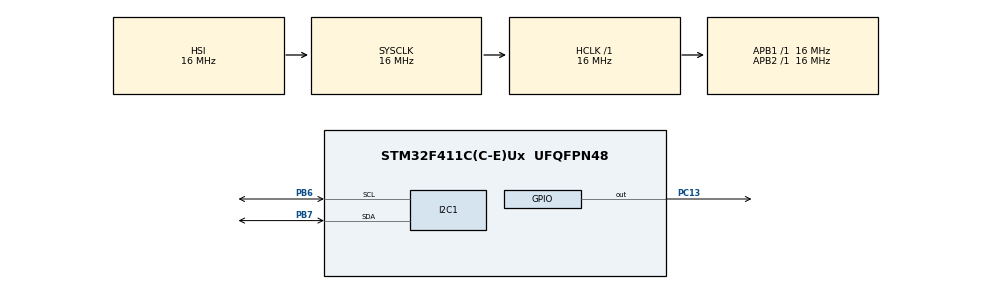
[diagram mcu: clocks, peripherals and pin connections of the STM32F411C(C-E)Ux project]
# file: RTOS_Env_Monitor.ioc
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FREERTOS.Tasks01=defaultTask,24,128,StartDefaultTask,Default,NULL,Dynamic,NULL,NULL
FREERTOS.configCHECK_FOR_STACK_OVERFLOW=1
FREERTOS.configUSE_MALLOC_FAILED_HOOK=1
Mcu.Family=STM32F4
Mcu.Name=STM32F411C(C-E)Ux
Mcu.Package=UFQFPN48
NVIC.PriorityGroup=NVIC_PRIORITYGROUP_4
NVIC.TIM1_UP_TIM10_IRQn=true\:15\:0\:false\:false\:true\:false\:false\:true\:true
NVIC.TimeBase=TIM1_UP_TIM10_IRQn
NVIC.TimeBaseIP=TIM1
PB6.Mode=I2C
PB6.Signal=I2C1_SCL
PB7.Mode=I2C
PB7.Signal=I2C1_SDA
PC13-ANTI_TAMP.Signal=GPIO_Output
ProjectManager.HeapSize=0x200
ProjectManager.StackSize=0x400
ProjectManager.TargetToolchain=STM32CubeIDE
RCC.AHBFreq_Value=16000000
RCC.APB1Freq_Value=16000000
RCC.APB2Freq_Value=16000000
RCC.CortexFreq_Value=16000000
RCC.HSE_VALUE=25000000
RCC.HSI_VALUE=16000000
RCC.LSE_VALUE=32768
RCC.SYSCLKFreq_VALUE=16000000
RCC.VCOOutputFreq_Value=192000000
VP_FREERTOS_VS_CMSIS_V2.Mode=CMSIS_V2
VP_SYS_VS_tim1.Mode=TIM1
board=custom

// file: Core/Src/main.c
/* USER CODE BEGIN Header */
/**
  ******************************************************************************
  * @file           : main.c
  * @brief          : Main program body
  ******************************************************************************
  * @attention
  *
  * Copyright (c) 2026 STMicroelectronics.
  * All rights reserved.
  *
  * This software is licensed under terms that can be found in the LICENSE file
  * in the root directory of this software component.
  * If no LICENSE file comes with this software, it is provided AS-IS.
  *
  ******************************************************************************
  */
/* USER CODE END Header */
#include "main.h"
#include "cmsis_os.h"

/* USER CODE BEGIN PD */
typedef struct {
	float temperature;
	float humidity;
	uint32_t timestamp;
} SensorData_t;
/* USER CODE END PD */

I2C_HandleTypeDef hi2c1;

/* Definitions for defaultTask */
osThreadId_t defaultTaskHandle;
const osThreadAttr_t defaultTask_attributes = {
  .name = "defaultTask",
  .stack_size = 128 * 4,
  .priority = (osPriority_t) osPriorityNormal,
};
/* USER CODE BEGIN PV */
osMessageQueueId_t sensorQueueHandle;
osMutexId_t i2cMutexHandle;
/* USER CODE END PV */

void SystemClock_Config(void);
static void MX_GPIO_Init(void);
static void MX_I2C1_Init(void);
void StartDefaultTask(void *argument);

/* USER CODE BEGIN PFP */
void Sensor_Task(void *argument);
void Comms_Task(void *argument);
void Processing_Task(void *argument);
void Display_Task(void *argument);
/* USER CODE END PFP */

int main(void)
{

  /* MCU Configuration--------------------------------------------------------*/

  /* Reset of all peripherals, Initializes the Flash interface and the Systick. */
  HAL_Init();

  /* Configure the system clock */
  SystemClock_Config();

  /* Initialize all configured peripherals */
  MX_GPIO_Init();
  MX_I2C1_Init();

  /* Init scheduler */
  osKernelInitialize();

  /* USER CODE BEGIN RTOS_MUTEX */
  /* add mutexes, ... */

  i2cMutexHandle = osMutexNew(NULL);
  /* USER CODE END RTOS_MUTEX */

  /* USER CODE BEGIN RTOS_QUEUES */
  /* add queues, ... */
  sensorQueueHandle = osMessageQueueNew(5, sizeof(SensorData_t), NULL);
  /* USER CODE END RTOS_QUEUES */

  /* Create the thread(s) */
  /* creation of defaultTask */
  defaultTaskHandle = osThreadNew(StartDefaultTask, NULL, &defaultTask_attributes);

  /* USER CODE BEGIN RTOS_THREADS */
  osThreadAttr_t sensor_attr = { .name = "SensorTask", .priority = osPriorityHigh, .stack_size = 128 * 4 };
  osThreadAttr_t comms_attr = { .name = "CommsTask", .priority = osPriorityAboveNormal, .stack_size = 128 * 4 };
  osThreadAttr_t process_attr = { .name = "ProcessTask", .priority = osPriorityNormal, .stack_size = 128 * 4 };
  osThreadAttr_t display_attr = { .name = "DisplayTask", .priority = osPriorityLow, .stack_size = 128 * 4 };

  osThreadNew(Sensor_Task, NULL, &sensor_attr);
  osThreadNew(Comms_Task, NULL, &comms_attr);
  osThreadNew(Processing_Task, NULL, &process_attr);
  osThreadNew(Display_Task, NULL, &display_attr);
  /* add threads, ... */
  /* USER CODE END RTOS_THREADS */

  /* Start scheduler */
  osKernelStart();

  /* We should never get here as control is now taken by the scheduler */

  /* Infinite loop */
  while (1)
  {

  }
}

void SystemClock_Config(void)
{
  RCC_OscInitTypeDef RCC_OscInitStruct = {0};
  RCC_ClkInitTypeDef RCC_ClkInitStruct = {0};

  /** Configure the main internal regulator output voltage
  */
  __HAL_RCC_PWR_CLK_ENABLE();
  __HAL_PWR_VOLTAGESCALING_CONFIG(PWR_REGULATOR_VOLTAGE_SCALE1);

  /** Initializes the RCC Oscillators according to the specified parameters
  * in the RCC_OscInitTypeDef structure.
  */
  RCC_OscInitStruct.OscillatorType = RCC_OSCILLATORTYPE_HSI;
  RCC_OscInitStruct.HSIState = RCC_HSI_ON;
  RCC_OscInitStruct.HSICalibrationValue = RCC_HSICALIBRATION_DEFAULT;
  RCC_OscInitStruct.PLL.PLLState = RCC_PLL_NONE;
  if (HAL_RCC_OscConfig(&RCC_OscInitStruct) != HAL_OK)
  {
    Error_Handler();
  }

  /** Initializes the CPU, AHB and APB buses clocks
  */
  RCC_ClkInitStruct.ClockType = RCC_CLOCKTYPE_HCLK|RCC_CLOCKTYPE_SYSCLK
                              |RCC_CLOCKTYPE_PCLK1|RCC_CLOCKTYPE_PCLK2;
  RCC_ClkInitStruct.SYSCLKSource = RCC_SYSCLKSOURCE_HSI;
  RCC_ClkInitStruct.AHBCLKDivider = RCC_SYSCLK_DIV1;
  RCC_ClkInitStruct.APB1CLKDivider = RCC_HCLK_DIV1;
  RCC_ClkInitStruct.APB2CLKDivider = RCC_HCLK_DIV1;

  if (HAL_RCC_ClockConfig(&RCC_ClkInitStruct, FLASH_LATENCY_0) != HAL_OK)
  {
    Error_Handler();
  }
}

static void MX_I2C1_Init(void)
{

  hi2c1.Instance = I2C1;
  hi2c1.Init.ClockSpeed = 100000;
  hi2c1.Init.DutyCycle = I2C_DUTYCYCLE_2;
  hi2c1.Init.OwnAddress1 = 0;
  hi2c1.Init.AddressingMode = I2C_ADDRESSINGMODE_7BIT;
  hi2c1.Init.DualAddressMode = I2C_DUALADDRESS_DISABLE;
  hi2c1.Init.OwnAddress2 = 0;
  hi2c1.Init.GeneralCallMode = I2C_GENERALCALL_DISABLE;
  hi2c1.Init.NoStretchMode = I2C_NOSTRETCH_DISABLE;
  if (HAL_I2C_Init(&hi2c1) != HAL_OK)
  {
    Error_Handler();
  }

}

static void MX_GPIO_Init(void)
{
  GPIO_InitTypeDef GPIO_InitStruct = {0};

  /* GPIO Ports Clock Enable */
  __HAL_RCC_GPIOC_CLK_ENABLE();
  __HAL_RCC_GPIOB_CLK_ENABLE();

  /*Configure GPIO pin Output Level */
  HAL_GPIO_WritePin(GPIOC, GPIO_PIN_13, GPIO_PIN_RESET);

  /*Configure GPIO pin : PC13 */
  GPIO_InitStruct.Pin = GPIO_PIN_13;
  GPIO_InitStruct.Mode = GPIO_MODE_OUTPUT_PP;
  GPIO_InitStruct.Pull = GPIO_NOPULL;
  GPIO_InitStruct.Speed = GPIO_SPEED_FREQ_LOW;
  HAL_GPIO_Init(GPIOC, &GPIO_InitStruct);

}

/* USER CODE BEGIN 4 */

extern I2C_HandleTypeDef hi2c1;

#include <math.h>
#include <stdlib.h>
float gaussian_noise(float mean, float stddev) {

    static float u1 = 0, u2 = 0;
    static int phase = 0;

    if (phase == 0) {
        u1 = (float)rand() / RAND_MAX;
        u2 = (float)rand() / RAND_MAX;
        phase = 1;
        return mean + stddev * sqrtf(-2.0f * logf(u1)) * cosf(2.0f * 3.14159f * u2);
    } else {
        phase = 0;
        return mean + stddev * sqrtf(-2.0f * logf(u1)) * sinf(2.0f * 3.14159f * u2);
    }
}

void Sensor_Task(void *argument){
    SensorData_t myData;
    uint32_t tick = 0;

    float base_temp = 22.0f;

    const int FAILURE_RATE = 20;

    for(;;){

        if (osMutexAcquire(i2cMutexHandle, osWaitForever) == osOK) {

            int simulated_i2c_status = (rand() % FAILURE_RATE == 0) ? HAL_TIMEOUT : HAL_OK;

            if (simulated_i2c_status == HAL_OK) {

                float drift = 3.0f * sinf((float)tick * 0.05f);
                float noise = gaussian_noise(0.0f, 0.5f);
                myData.temperature = base_temp + drift + noise;
                myData.humidity = 65.0f - (drift * 2.0f) + gaussian_noise(0.0f, 1.0f);

                if (myData.humidity < 30.0f) myData.humidity = 30.0f;
                if (myData.humidity > 95.0f) myData.humidity = 95.0f;

                myData.timestamp = osKernelGetTickCount();
                osMessageQueuePut(sensorQueueHandle, &myData, 0, 100);

                HAL_GPIO_TogglePin(GPIOC, GPIO_PIN_13);

            } else {

                myData.temperature = 25.0f;
                myData.humidity = 50.0f;
                myData.timestamp = osKernelGetTickCount();

                osMessageQueuePut(sensorQueueHandle, &myData, 0, 100);

                for(int i = 0; i < 5; i++) {
                    HAL_GPIO_TogglePin(GPIOC, GPIO_PIN_13);
                    osDelay(100);
                }
            }

            osMutexRelease(i2cMutexHandle);
        }

        tick++;
        osDelay(500);
    }
}

void Comms_Task(void *argument){
	for (;;) {
		osDelay(1000);
	}
}

void Processing_Task(void *argument){
	SensorData_t receivedData;
	for(;;){
		if (osMessageQueueGet(sensorQueueHandle, &receivedData, NULL, osWaitForever) == osOK){
			float temp_f = (receivedData.temperature * 9.0/5.0) + 32.0;
			(void)temp_f;

			for (int i=0; i<3;i++) {
				HAL_GPIO_TogglePin(GPIOC, GPIO_PIN_13);
				osDelay(250);
			}
		}

	}
}

void Display_Task(void *argument){
	for(;;){
		osDelay(2000);
	}
}

/* USER CODE END 4 */

void StartDefaultTask(void *argument)
{
  for(;;)
  {
    osDelay(1);
  }
}

void HAL_TIM_PeriodElapsedCallback(TIM_HandleTypeDef *htim)
{
  if (htim->Instance == TIM1)
  {
    HAL_IncTick();
  }
}

void Error_Handler(void)
{
  __disable_irq();
  while (1)
  {
  }
}

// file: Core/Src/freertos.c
/* USER CODE BEGIN Header */
/**
  ******************************************************************************
  * File Name          : freertos.c
  * Description        : Code for freertos applications
  ******************************************************************************
  * @attention
  *
  * Copyright (c) 2026 STMicroelectronics.
  * All rights reserved.
  *
  * This software is licensed under terms that can be found in the LICENSE file
  * in the root directory of this software component.
  * If no LICENSE file comes with this software, it is provided AS-IS.
  *
  ******************************************************************************
  */
/* USER CODE END Header */

#include "FreeRTOS.h"
#include "task.h"
#include "main.h"

/* Hook prototypes */
void vApplicationStackOverflowHook(xTaskHandle xTask, signed char *pcTaskName);
void vApplicationMallocFailedHook(void);

/* USER CODE BEGIN 4 */
void vApplicationStackOverflowHook(xTaskHandle xTask, signed char *pcTaskName)
{
   /* Run time stack overflow checking is performed if
   configCHECK_FOR_STACK_OVERFLOW is defined to 1 or 2. This hook function is
   called if a stack overflow is detected. */
	while(1) {

	  }
}
/* USER CODE END 4 */

/* USER CODE BEGIN 5 */
void vApplicationMallocFailedHook(void)
{
   /* vApplicationMallocFailedHook() will only be called if
   configUSE_MALLOC_FAILED_HOOK is set to 1 in FreeRTOSConfig.h. It is a hook
   function that will get called if a call to pvPortMalloc() fails.
   pvPortMalloc() is called internally by the kernel whenever a task, queue,
   timer or semaphore is created. It is also called by various parts of the
   demo application. If heap_1.c or heap_2.c are used, then the size of the
   heap available to pvPortMalloc() is defined by configTOTAL_HEAP_SIZE in
   FreeRTOSConfig.h, and the xPortGetFreeHeapSize() API function can be used
   to query the size of free heap space that remains (although it does not
   provide information on how the remaining heap might be fragmented). */
}
/* USER CODE END 5 */
